# PIC32MZ1025W104132 register map
Vendor: Microchip
Registers are 32-bit, read-write, no defined reset value unless marked. A register's access mark holds for its fields unless they carry their own. Addresses are absolute, and some are shared; only a register's first bit layout is shown; [hi:lo] are bit positions.

## ETH
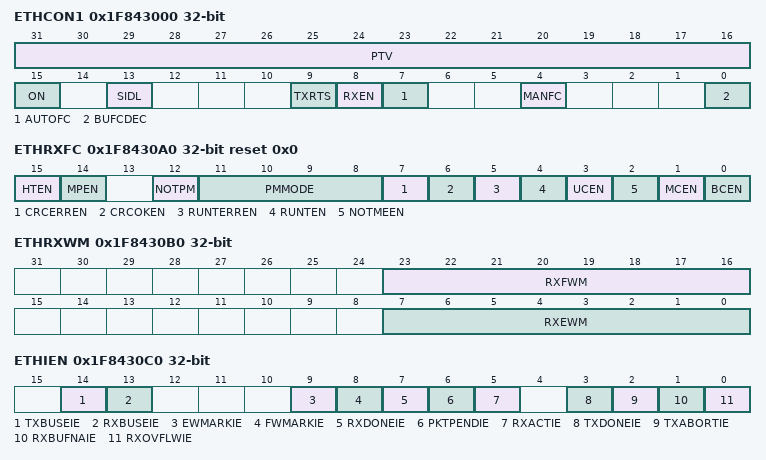
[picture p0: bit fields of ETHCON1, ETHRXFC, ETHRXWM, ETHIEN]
0x1F843000 ETHCON1 — (power-on value 0000000000000000000xxx000xx0xxx0)
  [31:16] PTV, [15] ON, [13] SIDL, [9] TXRTS, [8] RXEN, [7] AUTOFC, [4] MANFC, [0] BUFCDEC
0x1F843010 ETHCON2 — (power-on value xxxxxxxxxxxxxxxxxxxxx0000000xxxx)
  [10:4] RXBUF_SZ
0x1F843020 ETHTXST reset 0x0
  [2] TXSTADDR
0x1F843030 ETHRXST reset 0x0
  [2] RXSTADDR
0x1F843040 ETHHT0 reset 0x0
  [31:0] HT
0x1F843050 ETHHT1 reset 0x0
  [31:0] HT
0x1F843060 ETHPMM0 — (power-on value xxxxxxxxxxxxxxxxxxxxxxxxxxxxxxxx)
  [31:0] PMM
0x1F843070 ETHPMM1 reset 0x0
  [31:0] PMM
0x1F843080 ETHPMCS — (power-on value xxxxxxxxxxxxxxxx0000000000000000)
  [15:0] PMCS
0x1F843090 ETHPMO — (power-on value xxxxxxxxxxxxxxxx0000000000000000)
  [15:0] PMO
0x1F8430A0 ETHRXFC reset 0x0
  [15] HTEN, [14] MPEN, [12] NOTPM, [11:8] PMMODE, [7] CRCERREN, [6] CRCOKEN, [5] RUNTERREN, [4] RUNTEN, [3] UCEN, [2] NOTMEEN, [1] MCEN, [0] BCEN
0x1F8430B0 ETHRXWM — (power-on value xxxxxxxx00000000xxxxxxxx00000000)
  [23:16] RXFWM, [7:0] RXEWM
0x1F8430C0 ETHIEN — (power-on value xxxxxxxxxxxxxxxxx00xxx00000x0000)
  [14] TXBUSEIE, [13] RXBUSEIE, [9] EWMARKIE, [8] FWMARKIE, [7] RXDONEIE, [6] PKTPENDIE, [5] RXACTIE, [3] TXDONEIE, [2] TXABORTIE, [1] RXBUFNAIE, [0] RXOVFLWIE
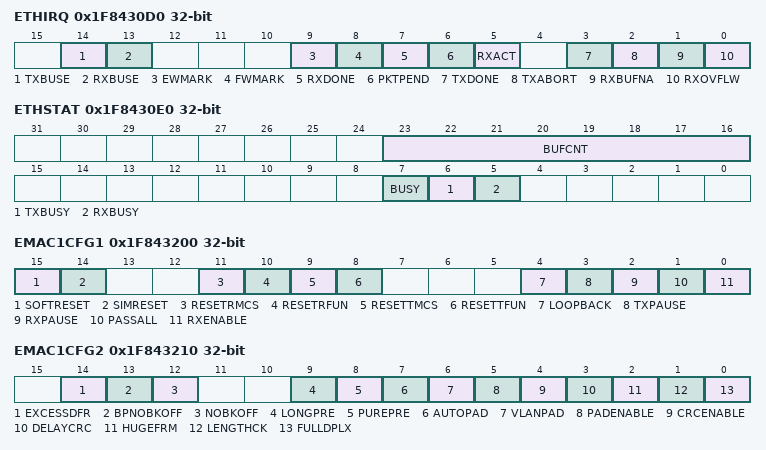
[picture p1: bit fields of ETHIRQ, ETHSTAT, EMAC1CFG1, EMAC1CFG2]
0x1F8430D0 ETHIRQ — (power-on value xxxxxxxxxxxxxxxxx00xxx00000x0000)
  [14] TXBUSE, [13] RXBUSE, [9] EWMARK ro, [8] FWMARK ro, [7] RXDONE, [6] PKTPEND ro, [5] RXACT, [3] TXDONE, [2] TXABORT, [1] RXBUFNA, [0] RXOVFLW
0x1F8430E0 ETHSTAT — (power-on value xxxxxxxx00000000xxxxxxxx000xxxxx)
  [23:16] BUFCNT, [7] BUSY, [6] TXBUSY, [5] RXBUSY
0x1F843100 ETHRXOVFLOW — (power-on value xxxxxxxxxxxxxxxx0000000000000000)
  [15:0] RXOVFLWCNT
0x1F843110 ETHFRMTXOK — (power-on value xxxxxxxxxxxxxxxx0000000000000000)
  [0] FRMTXOKCNT
0x1F843120 ETHSCOLFRM — (power-on value xxxxxxxxxxxxxxxx0000000000000000)
  [15:0] SCOLFRMCNT
0x1F843130 ETHMCOLFRM — (power-on value xxxxxxxxxxxxxxxx0000000000000000)
  [15:0] MCOLFRMCNT
0x1F843140 ETHFRMRXOK — (power-on value xxxxxxxxxxxxxxxx0000000000000000)
  [15:0] FRMRXOKCNT
0x1F843150 ETHFCSERR — (power-on value xxxxxxxxxxxxxxxx0000000000000000)
  [15:0] FCSERRCNT
0x1F843160 ETHALGNERR — (power-on value xxxxxxxxxxxxxxxx0000000000000000)
  [15:0] ALGNERRCNT
0x1F843200 EMAC1CFG1 — (power-on value xxxxxxxxxxxxxxxx10xx0000xxx01101)
  [15] SOFTRESET, [14] SIMRESET, [11] RESETRMCS, [10] RESETRFUN, [9] RESETTMCS, [8] RESETTFUN, [4] LOOPBACK, [3] TXPAUSE, [2] RXPAUSE, [1] PASSALL, [0] RXENABLE
0x1F843210 EMAC1CFG2 — (power-on value xxxxxxxxxxxxxxxxx100xx0010110100)
  [14] EXCESSDFR, [13] BPNOBKOFF, [12] NOBKOFF, [9] LONGPRE, [8] PUREPRE, [7] AUTOPAD, [6] VLANPAD, [5] PADENABLE, [4] CRCENABLE, [3] DELAYCRC, [2] HUGEFRM, [1] LENGTHCK, [0] FULLDPLX
0x1F843220 EMAC1IPGT — (power-on value xxxxxxxxxxxxxxxxxxxxxxxxx0010010)
  [6:0] B2BIPKTGP
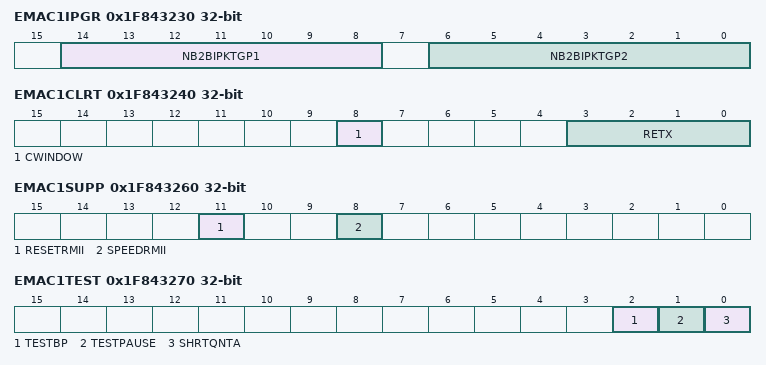
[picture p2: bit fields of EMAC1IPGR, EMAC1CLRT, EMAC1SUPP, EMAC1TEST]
0x1F843230 EMAC1IPGR — (power-on value xxxxxxxxxxxxxxxxx0001100x0010010)
  [14:8] NB2BIPKTGP1, [6:0] NB2BIPKTGP2
0x1F843240 EMAC1CLRT — (power-on value xxxxxxxxxxxxxxxxxx110111xxxx1111)
  [8] CWINDOW, [3:0] RETX
0x1F843250 EMAC1MAXF — (power-on value xxxxxxxxxxxxxxxx0000010111101110)
  [0] MACMAXF
0x1F843260 EMAC1SUPP — (power-on value xxxxxxxxxxxxxxxx0xx10xx000000x00)
  [11] RESETRMII, [8] SPEEDRMII
0x1F843270 EMAC1TEST — (power-on value xxxxxxxxxxxxxxxxxxxxxxxxxxxxx000)
  [2] TESTBP, [1] TESTPAUSE, [0] SHRTQNTA
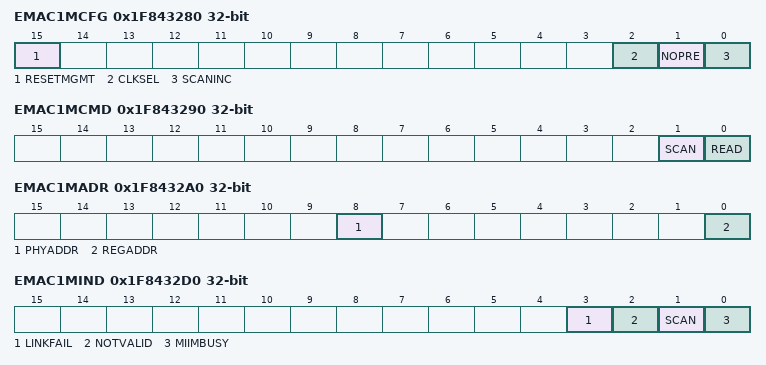
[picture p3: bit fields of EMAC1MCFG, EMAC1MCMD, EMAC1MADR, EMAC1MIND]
0x1F843280 EMAC1MCFG — (power-on value xxxxxxxxxxxxxxxx0xxxxxxxxx100000)
  [15] RESETMGMT, [2] CLKSEL, [1] NOPRE, [0] SCANINC
0x1F843290 EMAC1MCMD — (power-on value xxxxxxxxxxxxxxxxxxxxxxxxxxxxxx00)
  [1] SCAN, [0] READ
0x1F8432A0 EMAC1MADR — (power-on value xxxxxxxxxxxxxxxxxxx00001xxx00000)
  [8] PHYADDR, [0] REGADDR
0x1F8432B0 EMAC1MWTD — (power-on value xxxxxxxxxxxxxxxx0000000000000000)
  [15:0] MWTD
0x1F8432C0 EMAC1MRDD — (power-on value xxxxxxxxxxxxxxxx0000000000000000)
  [0] MRDD
0x1F8432D0 EMAC1MIND — (power-on value xxxxxxxxxxxxxxxxxxxxxxxxxxxx0000)
  [3] LINKFAIL, [2] NOTVALID, [1] SCAN, [0] MIIMBUSY
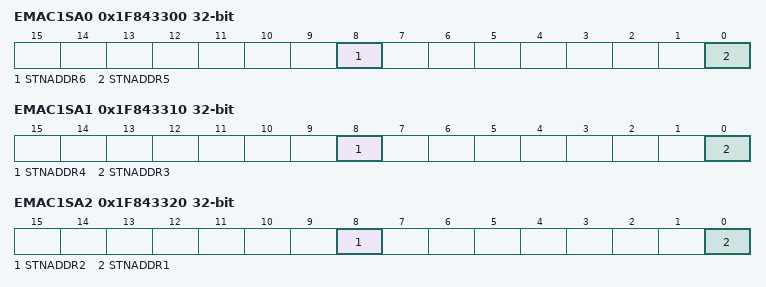
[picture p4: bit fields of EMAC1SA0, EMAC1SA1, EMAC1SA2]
0x1F843300 EMAC1SA0 — (power-on value xxxxxxxxxxxxxxxxxxxxxxxxxxxxxxxx)
  [8] STNADDR6, [0] STNADDR5
0x1F843310 EMAC1SA1 — (power-on value xxxxxxxxxxxxxxxxxxxxxxxxxxxxxxxx)
  [8] STNADDR4, [0] STNADDR3
0x1F843320 EMAC1SA2 — (power-on value xxxxxxxxxxxxxxxxxxxxxxxxxxxxxxxx)
  [8] STNADDR2, [0] STNADDR1
